# MIMXRT1062 register map
Vendor: nxp.com; File version: 1.0
CPU: CM7 r0p1, little endian, MPU, FPU, VTOR, 4 interrupt priority bits
Registers are 32-bit, read-write, reset 0x0 unless marked. A register's access mark holds for its fields unless they carry their own. Offsets are from the block's base; [hi:lo] are bit positions; {n}, {i} and the like mark numbered series; 'fields as' and 'values as' point back to an identical list.

## SEMC
Base 0x402F0000
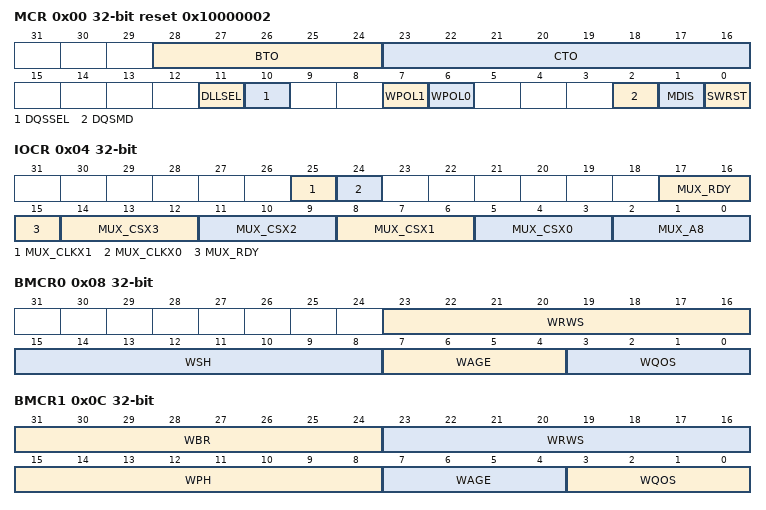
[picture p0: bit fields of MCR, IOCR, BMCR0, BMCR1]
0x00 MCR reset 0x10000002 — Module Control Register
  [28:24] BTO — Bus timeout cycles
    0=255*1; {v}=255*2 - 255*2^30 (v=1..9); 31=255*2^31
  [23:16] CTO — Command Execution timeout cycles
  [11] DLLSEL — Select DLL delay chain clock input.
    0=DLL delay chain clock input is from NAND device's DQS pad. For NAND synchronous mode only.; 1=DLL delay chain clock input is from internal clock. For SDRAM, NOR and SRAM synchronous mode only.
  [10] DQSSEL — Select DQS source when DQSMD and DLLSEL both set.
    0=SDRAM/NOR/SRAM read clock source is from DQS pad in synchronous mode; 1=SDRAM/NOR/SRAM read clock source is from DLL delay chain in synchronous mode
  [7] WPOL1 — WAIT/RDY# polarity for NAND
    0=Low active; 1=High active
  [6] WPOL0 — WAIT/RDY# polarity for NOR/PSRAM
    0=Low active; 1=High active
  [2] DQSMD — DQS (read strobe) mode
    0=Dummy read strobe loopbacked internally; 1=Dummy read strobe loopbacked from DQS pad or DLL delay chain. Details information at descriptions of DQSSEL bit.
  [1] MDIS — Module Disable
    0=Module enabled; 1=Module disabled
  [0] SWRST — Software Reset
0x04 IOCR — IO Mux Control Register
  [25] MUX_CLKX1 — SEMC_CLKX1 function selection
    0=NOR clock; 1=SRAM clock
  [24] MUX_CLKX0 — SEMC_CLKX0 function selection
    0=NOR clock; 1=SRAM clock
  [17:15] MUX_RDY — SEMC_RDY function selection
    0=NAND Ready/Wait# input; 1=SDRAM CS1; 2=SDRAM CS2; 3=SDRAM CS3; 4=NOR CE#; 5=PSRAM CE#; 6=DBI CSX; 7=NOR/PSRAM Address bit 27
  [3n+5:3n+3] MUX_CSX{n} (n=0..3) — SEMC_CSX{n} output selection
    0=NOR/PSRAM Address bit {n+24} (A{n+24}); 1=SDRAM CS1; 2=SDRAM CS2; 3=SDRAM CS3; 4=NAND CE#; 5=NOR CE#; 6=PSRAM CE#; 7=DBI CSX
  [2:0] MUX_A8 — SEMC_A8 output selection
    0=SDRAM Address bit (A8); 1=NAND CE#; 2=NOR CE#; 3=PSRAM CE#; 4=DBI CSX; 5=SDRAM Address bit (A8); 6=SDRAM Address bit (A8); 7=SDRAM Address bit (A8)
0x08 BMCR0 — Master Bus (AXI) Control Register 0
  [23:16] WRWS — Weight of Slave Hit (Read/Write switch)
  [15:8] WSH — Weight of Slave Hit (no read/write switch)
  [7:4] WAGE — Weight of Aging
  [3:0] WQOS — Weight of QoS
0x0C BMCR1 — Master Bus (AXI) Control Register 1
  [31:24] WBR — Weight of Bank Rotation
  [23:16] WRWS — Weight of Read/Write switch
  [15:8] WPH — Weight of Page Hit
  [7:4] WAGE — Weight of Aging
  [3:0] WQOS — Weight of QoS
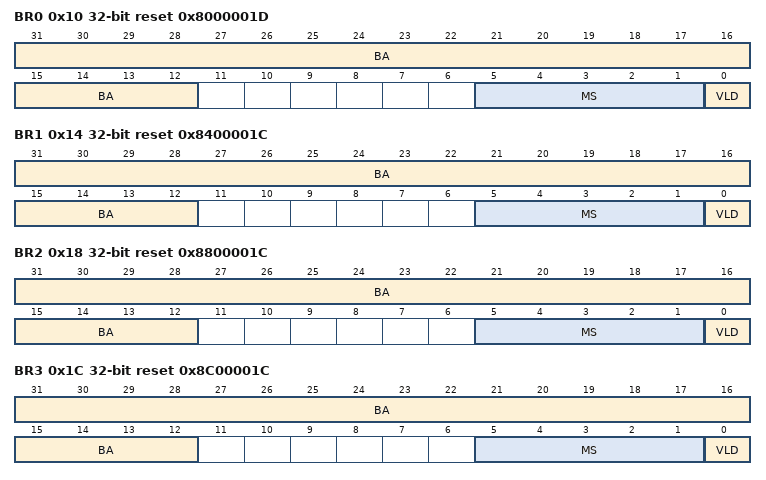
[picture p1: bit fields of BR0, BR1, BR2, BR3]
0x10 BR0 reset 0x8000001D — Base Register 0 (For SDRAM CS0 device)
  [31:12] BA — Base Address
  [5:1] MS — Memory size
    0=4KB; 1=8KB; 2=16KB; 3=32KB; 4=64KB; 5=128KB; 6=256KB; 7=512KB; 8=1MB; 9=2MB; 10=4MB; 11=8MB; 12=16MB; 13=32MB; 14=64MB; 15=128MB; 16=256MB; 17=512MB; 18=1GB; 19=2GB; {v}=4GB (v=20..31)
  [0] VLD — Valid
0x14 BR1 reset 0x8400001C — Base Register 1 (For SDRAM CS1 device)
  fields as BR0
0x18 BR2 reset 0x8800001C — Base Register 2 (For SDRAM CS2 device)
  fields as BR0
0x1C BR3 reset 0x8C00001C — Base Register 3 (For SDRAM CS3 device)
  fields as BR0
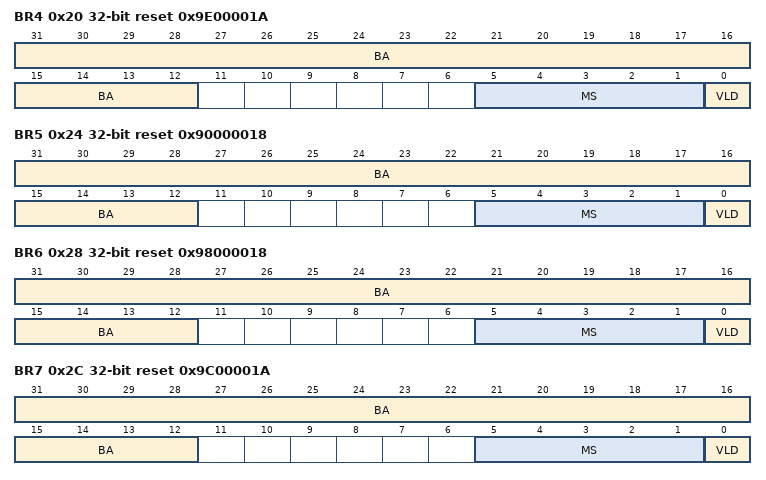
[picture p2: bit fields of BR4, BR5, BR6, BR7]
0x20 BR4 reset 0x9E00001A — Base Register 4 (For NAND device)
  fields as BR0
0x24 BR5 reset 0x90000018 — Base Register 5 (For NOR device)
  fields as BR0
0x28 BR6 reset 0x98000018 — Base Register 6 (For PSRAM device)
  fields as BR0
0x2C BR7 reset 0x9C00001A — Base Register 7 (For DBI-B (MIPI Display Bus Interface Type B) device)
  fields as BR0
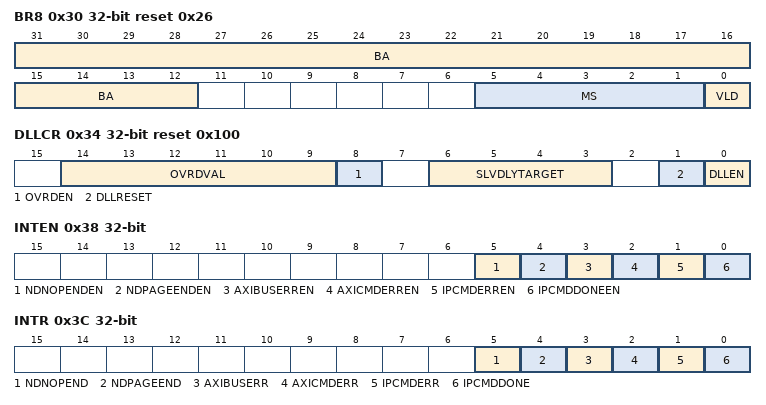
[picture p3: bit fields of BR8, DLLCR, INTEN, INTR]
0x30 BR8 reset 0x26 — Base Register 8 (For NAND device)
  fields as BR0
0x34 DLLCR reset 0x100 — DLL Control Register
  [14:9] OVRDVAL — Slave clock delay line delay cell number selection override value.
  [8] OVRDEN — Slave clock delay line delay cell number selection override enable.
  [6:3] SLVDLYTARGET — The delay target for slave delay line is: ((SLVDLYTARGET+1) * 1/32 * clock cycle of reference clock (ipgclock).
  [1] DLLRESET — Software could force a reset on DLL by setting this field to 0x1. This will cause the DLL to lose lock and re-calibrate to detect an ref_clock half period phase shift. The reset action is edge triggered, so software need to clear this bit after set this bit (no delay limitation).
  [0] DLLEN — DLL calibration enable.
0x38 INTEN — Interrupt Enable Register
  [5] NDNOPENDEN — This bit enable/disable the NDNOPEND interrupt generation.
    0=Disable; 1=Enable
  [4] NDPAGEENDEN — This bit enable/disable the NDPAGEEND interrupt generation.
    0=Disable; 1=Enable
  [3] AXIBUSERREN — AXI bus error interrupt enable
  [2] AXICMDERREN — AXI command error interrupt enable
  [1] IPCMDERREN — IP command error interrupt enable
  [0] IPCMDDONEEN — IP command done interrupt enable
0x3C INTR — Interrupt Enable Register
  [5] NDNOPEND write-1-clears — This interrupt is generated when all pending AXI write command to NAND is finished on NAND interface.
  [4] NDPAGEEND write-1-clears — This interrupt is generated when the last address of one page in NAND device is written by AXI command
  [3] AXIBUSERR write-1-clears — AXI bus error interrupt
  [2] AXICMDERR write-1-clears — AXI command error interrupt
  [1] IPCMDERR write-1-clears — IP command error done interrupt
  [0] IPCMDDONE write-1-clears — IP command normal done interrupt
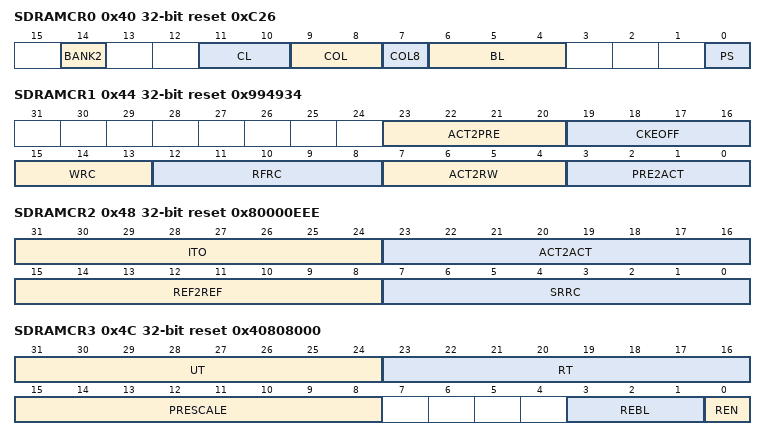
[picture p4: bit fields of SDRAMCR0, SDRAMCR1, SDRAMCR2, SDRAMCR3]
0x40 SDRAMCR0 reset 0xC26 — SDRAM control register 0
  [14] BANK2 — 2 Bank selection bit
    0=SDRAM device has 4 banks; 1=SDRAM device has 2 banks
  [11:10] CL — CAS Latency
    0=1; 1=1; 2=2; 3=3
  [9:8] COL — Column address bit number
    0=12 bit; 1=11 bit; 2=10 bit; 3=9 bit
  [7] COL8 — Column 8 selection bit
    0=Column address bit number is decided by COL field; 1=Column address bit number is 8. COL field is ignored.
  [6:4] BL — Burst Length
    0=1; 1=2; 2=4; {v}=8 (v=3..7)
  [0] PS — Port Size
    0=8bit; 1=16bit
0x44 SDRAMCR1 reset 0x994934 — SDRAM control register 1
  [23:20] ACT2PRE — ACT to Precharge minimum time
  [19:16] CKEOFF — CKE OFF minimum time
  [15:13] WRC — Write recovery time
  [12:8] RFRC — Refresh recovery time
  [7:4] ACT2RW — ACT to Read/Write wait time
  [3:0] PRE2ACT — PRECHARGE to ACT/Refresh wait time
0x48 SDRAMCR2 reset 0x80000EEE — SDRAM control register 2
  [31:24] ITO — SDRAM Idle timeout
    0=IDLE timeout period is 256*Prescale period; {v}=IDLE timeout period is ITO*Prescale period (v=1..9)
  [23:16] ACT2ACT — ACT to ACT wait time
  [15:8] REF2REF — Refresh to Refresh wait time
  [7:0] SRRC — Self Refresh Recovery time
0x4C SDRAMCR3 reset 0x40808000 — SDRAM control register 3
  [31:24] UT — Refresh urgent threshold
    0=256*Prescaler period; {v}=UT*Prescaler period (v=1..9)
  [23:16] RT — Refresh timer period
    0=256*Prescaler period; {v}=RT*Prescaler period (v=1..9)
  [15:8] PRESCALE — Prescaler timer period
    0=256*16 cycle; {v}=PRESCALE*16 cycle (v=1..9)
  [3:1] REBL — Refresh burst length
    {v}={v+1} (v=0..7)
  [0] REN — Refresh enable
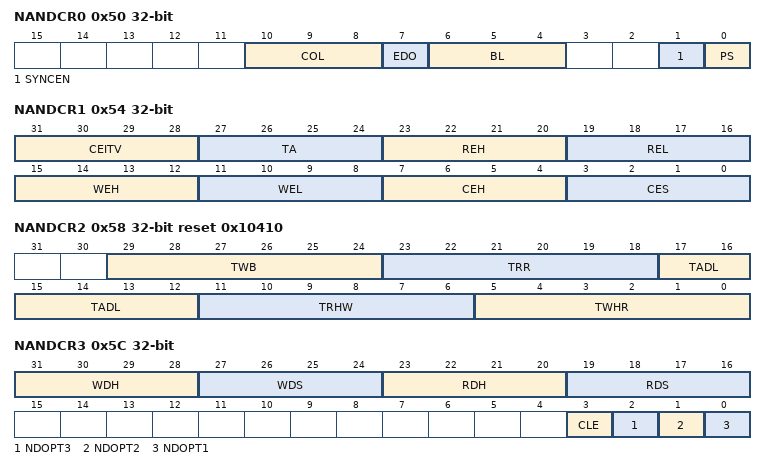
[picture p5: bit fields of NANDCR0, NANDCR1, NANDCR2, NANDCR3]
0x50 NANDCR0 — NAND control register 0
  [10:8] COL — Column address bit number
    0=16; 1=15; 2=14; 3=13; 4=12; 5=11; 6=10; 7=9
  [7] EDO — EDO mode enabled
    0=EDO mode disabled; 1=EDO mode enabled
  [6:4] BL — Burst Length
    0=1; 1=2; 2=4; 3=8; 4=16; 5=32; 6=64; 7=64
  [1] SYNCEN — Select NAND controller mode.
    0=Asynchronous mode is enabled; 1=Synchronous mode is enabled
  [0] PS — Port Size
    0=8bit; 1=16bit
0x54 NANDCR1 — NAND control register 1
  [31:28] CEITV — CE# interval time
  [27:24] TA — Turnaround time
  [23:20] REH — RE# HIGH time
  [19:16] REL — RE# LOW time
  [15:12] WEH — WE# HIGH time
  [11:8] WEL — WE# LOW time
  [7:4] CEH — CE hold time
  [3:0] CES — CE setup time
0x58 NANDCR2 reset 0x10410 — NAND control register 2
  [29:24] TWB — WE# HIGH to busy wait time
  [23:18] TRR — Ready to RE# LOW min wait time
  [17:12] TADL — ALE to WRITE Data start wait time
  [11:6] TRHW — RE# HIGH to WE# LOW wait time
  [5:0] TWHR — WE# HIGH to RE# LOW wait time
0x5C NANDCR3 — NAND control register 3
  [31:28] WDH — Write Data Hold cycle time.
  [27:24] WDS — Write Data Setup cycle time.
  [23:20] RDH — Read Data Hold cycle time.
  [19:16] RDS — Read Data Setup cycle time.
  [3] CLE — NAND CLE Option
  [2] NDOPT3 — NAND option bit 3
  [1] NDOPT2 — NAND option bit 2
  [0] NDOPT1 — NAND option bit 1
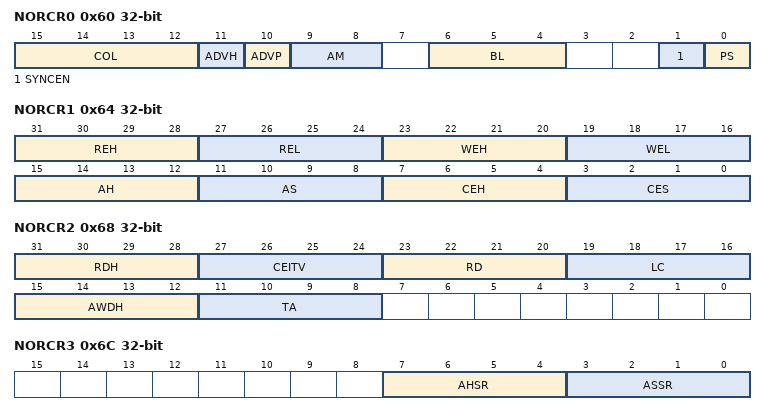
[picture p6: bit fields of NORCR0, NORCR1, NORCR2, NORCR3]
0x60 NORCR0 — NOR control register 0
  [15:12] COL — Column Address bit width
    0=12 Bits; 1=11 Bits; 2=10 Bits; 3=9 Bits; 4=8 Bits; 5=7 Bits; 6=6 Bits; 7=5 Bits; 8=4 Bits; 9=3 Bits; 10=2 Bits; {v}=12 Bits (v=11..15)
  [11] ADVH — ADV# level control during address hold state
    0=ADV# is high during address hold state; 1=ADV# is low during address hold state
  [10] ADVP — ADV# polarity
    0=ADV# is Low Active. In ASYNC mode, device sample address with ADV# rise edge; In SYNC mode, device sample address when ADV# is LOW.; 1=ADV# is High Active. In ASYNC mode, device sample address with ADV# fall edge; In SYNC mode, device sample address when ADV# is HIGH.
  [9:8] AM — Address Mode
    0=Address/Data MUX mode; 1=Advanced Address/Data MUX mode; 2=Address/Data non-MUX mode; 3=Address/Data non-MUX mode
  [6:4] BL — Burst Length
    0=1; 1=2; 2=4; 3=8; 4=16; 5=32; 6=64; 7=64
  [1] SYNCEN — Select NOR controller mode.
    values as NANDCR0.SYNCEN
  [0] PS — Port Size
    0=8bit; 1=16bit
0x64 NORCR1 — NOR control register 1
  [31:28] REH — RE HIGH time (REH+1) cycle
  [27:24] REL — RE LOW time (REL+1) cycle
  [23:20] WEH — WE HIGH time (WEH+1) cycle
  [19:16] WEL — WE LOW time (WEL+1) cycle
  [15:12] AH — Address hold time
  [11:8] AS — Address setup time
  [7:4] CEH — CE hold min time (CEH+1) cycle
  [3:0] CES — CE setup time cycle
0x68 NORCR2 — NOR control register 2
  [31:28] RDH — Read cycle hold time
  [27:24] CEITV — CE# interval min time
  [23:20] RD — Read cycle time
  [19:16] LC — Latency count
  [15:12] AWDH — Address to write data hold time cycle
  [11:8] TA — Turnaround time cycle
0x6C NORCR3 — NOR control register 3
  [7:4] AHSR — Address hold time for synchronous read
  [3:0] ASSR — Address setup time for synchronous read
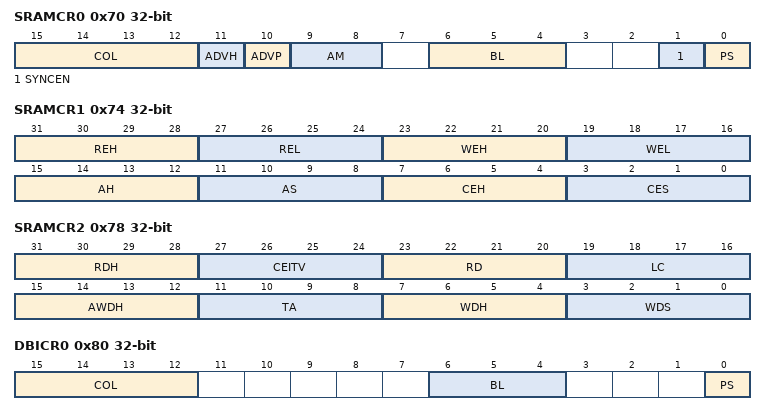
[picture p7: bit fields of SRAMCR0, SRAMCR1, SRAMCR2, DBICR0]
0x70 SRAMCR0 — SRAM control register 0
  [15:12] COL — Column Address bit width
    values as NORCR0.COL
  [11] ADVH — ADV# level control during address hold state
    values as NORCR0.ADVH
  [10] ADVP — ADV# polarity
    values as NORCR0.ADVP
  [9:8] AM — Address Mode
    values as NORCR0.AM
  [6:4] BL — Burst Length
    0=1; 1=2; 2=4; 3=8; 4=16; 5=32; 6=64; 7=64
  [1] SYNCEN — Select SRAM controller mode.
    values as NANDCR0.SYNCEN
  [0] PS — Port Size
    0=8bit; 1=16bit
0x74 SRAMCR1 — SRAM control register 1
  [31:28] REH — RE HIGH time (REH+1) cycle
  [27:24] REL — RE LOW time (REL+1) cycle
  [23:20] WEH — WE HIGH time (WEH+1) cycle
  [19:16] WEL — WE LOW time (WEL+1) cycle
  [15:12] AH — Address hold time
  [11:8] AS — Address setup time
  [7:4] CEH — CE hold min time
  [3:0] CES — CE setup time cycle
0x78 SRAMCR2 — SRAM control register 2
  [31:28] RDH — Read cycle hold time
  [27:24] CEITV — CE# interval min time
  [23:20] RD — Read cycle time
  [19:16] LC — Latency count
  [15:12] AWDH — Address to write data hold time cycle
  [11:8] TA — Turnaround time cycle
  [7:4] WDH — Write Data hold time WDH cycle
  [3:0] WDS — Write Data setup time (WDS+1) cycle
0x7C SRAMCR3 — SRAM control register 3
0x80 DBICR0 — DBI-B control register 0
  [15:12] COL — Column Address bit width
    values as NORCR0.COL
  [6:4] BL — Burst Length
    0=1; 1=2; 2=4; 3=8; 4=16; 5=32; 6=64; 7=64
  [0] PS — Port Size
    0=8bit; 1=16bit
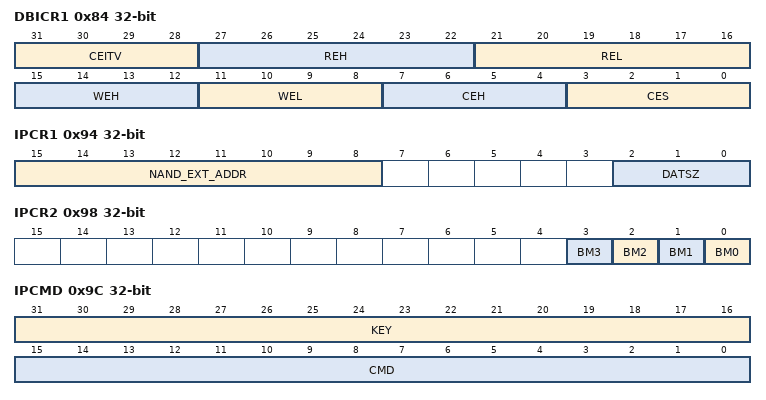
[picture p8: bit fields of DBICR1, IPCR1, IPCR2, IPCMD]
0x84 DBICR1 — DBI-B control register 1
  [31:28] CEITV — CSX interval min time
  [27:22] REH — RDX High Time
  [21:16] REL — RDX Low Time
  [15:12] WEH — WRX High Time
  [11:8] WEL — WRX Low Time
  [7:4] CEH — CSX Hold Time
  [3:0] CES — CSX Setup Time
0x90 IPCR0 — IP Command control register 0
  [31:0] SA — Slave address
0x94 IPCR1 — IP Command control register 1
  [15:8] NAND_EXT_ADDR — NAND Extended Address
  [2:0] DATSZ — Data Size in Byte
    0=4; {v}={v} (v=1..4); 5=4; 6=4; 7=4
0x98 IPCR2 — IP Command control register 2
  [all] fields
    0=Byte Unmasked; 1=Byte Masked
  [n] BM{n} (n=0..3) — Byte Mask for Byte {n} (IPTXD bit {8n+7}:{8n})
0x9C IPCMD — IP Command register
  [31:16] KEY wo — This field should be written with 0xA55A when trigging an IP command for all device types
  [15:0] CMD — SDRAM Commands: 0x8: READ 0x9: WRITE 0xA: MODESET 0xB: ACTIVE 0xC: AUTO REFRESH 0xD: SELF REFRESH 0xE: PRECHARGE 0xF: PRECHARGE ALL Others: RSVD SELF REFRESH will be sent to all SDRAM devices because they shared same SEMC_CLK pin
0xA0 IPTXDAT — TX DATA register (for IP Command)
  [31:0] DAT
0xB0 IPRXDAT ro — RX DATA register (for IP Command)
  [31:0] DAT
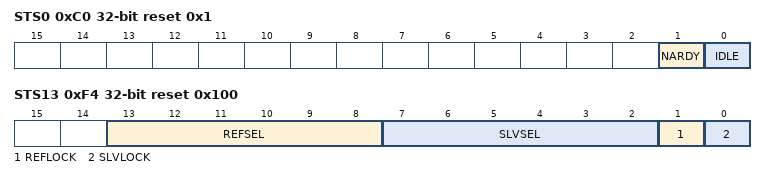
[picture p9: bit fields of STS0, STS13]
0xC0 STS0 ro reset 0x1 — Status register 0
  [1] NARDY — Indicating NAND device Ready/WAIT# pin level.
    0=NAND device is not ready; 1=NAND device is ready
  [0] IDLE — Indicating whether SEMC is in IDLE state.
0xC4 STS1 ro — Status register 1
0xC8 STS2 ro — Status register 2
  [3] NDWRPEND — This field indicating whether there is pending AXI command (write) to NAND device.
    0=No pending; 1=Pending
{0xC0+4i} STS{i} ro (i=3..11) — Status register {i}
0xF0 STS12 ro — Status register 12
  [31:0] NDADDR — This field indicating the last write address (AXI command) to NAND device (without base address in SEMC_BR4).
0xF4 STS13 ro reset 0x100 — Status register 13
  [13:8] REFSEL — Sample clock reference delay line delay cell number selection.
  [7:2] SLVSEL — Sample clock slave delay line delay cell number selection .
  [1] REFLOCK — Sample clock reference delay line locked.
  [0] SLVLOCK — Sample clock slave delay line locked.
0xF8 STS14 ro — Status register 14
0xFC STS15 ro — Status register 15
